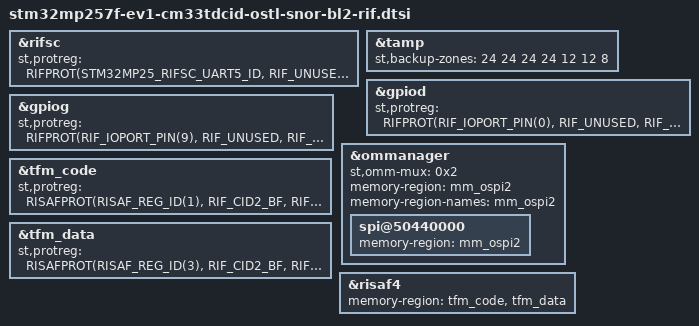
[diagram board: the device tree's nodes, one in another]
// SPDX-License-Identifier: (GPL-2.0-only OR BSD-3-Clause)
/*
 * Copyright (C) STMicroelectronics 2022 - All Rights Reserved
 */

/*
 * stm32mp257f device tree configuration
 * Project : ostl
 * Generated by XLmx tool version 2.8 - 2/28/2025 4:09:34 PM
 */

&rifsc {
	st,protreg = <
		RIFPROT(STM32MP25_RIFSC_UART5_ID, RIF_UNUSED, RIF_UNLOCK, RIF_SEC, RIF_PRIV, RIF_CID2, RIF_SEM_DIS, RIF_CFEN)
		RIFPROT(STM32MP25_RIFSC_I2C7_ID, RIF_UNUSED, RIF_UNLOCK, RIF_SEC, RIF_PRIV, RIF_CID2, RIF_SEM_DIS, RIF_CFEN)
		RIFPROT(STM32MP25_RIFSC_RNG_ID, RIF_UNUSED, RIF_UNLOCK, RIF_SEC, RIF_PRIV, RIF_CID2, RIF_SEM_DIS, RIF_CFEN)
	>;
};

&tamp {
	st,backup-zones = <24 24 24 24 12 12 8>;
};

&gpiod {
	st,protreg = <
		RIFPROT(RIF_IOPORT_PIN(0), RIF_UNUSED, RIF_UNLOCK, RIF_SEC, RIF_PRIV, RIF_CID2, RIF_SEM_DIS, RIF_CFEN)
		RIFPROT(RIF_IOPORT_PIN(3), RIF_UNUSED, RIF_UNLOCK, RIF_SEC, RIF_PRIV, RIF_CID2, RIF_SEM_DIS, RIF_CFEN)
		RIFPROT(RIF_IOPORT_PIN(4), RIF_UNUSED, RIF_UNLOCK, RIF_SEC, RIF_PRIV, RIF_CID2, RIF_SEM_DIS, RIF_CFEN)
		RIFPROT(RIF_IOPORT_PIN(5), RIF_UNUSED, RIF_UNLOCK, RIF_SEC, RIF_PRIV, RIF_CID2, RIF_SEM_DIS, RIF_CFEN)
		RIFPROT(RIF_IOPORT_PIN(6), RIF_UNUSED, RIF_UNLOCK, RIF_SEC, RIF_PRIV, RIF_CID2, RIF_SEM_DIS, RIF_CFEN)
		RIFPROT(RIF_IOPORT_PIN(7), RIF_UNUSED, RIF_UNLOCK, RIF_SEC, RIF_PRIV, RIF_CID2, RIF_SEM_DIS, RIF_CFEN)
		RIFPROT(RIF_IOPORT_PIN(14), RIF_UNUSED, RIF_UNLOCK, RIF_SEC, RIF_PRIV, RIF_CID2, RIF_SEM_DIS, RIF_CFEN)
		RIFPROT(RIF_IOPORT_PIN(15), RIF_UNUSED, RIF_UNLOCK, RIF_SEC, RIF_PRIV, RIF_CID2, RIF_SEM_DIS, RIF_CFEN)
	>;
};

&gpiog {
	st,protreg = <
		RIFPROT(RIF_IOPORT_PIN(9), RIF_UNUSED, RIF_UNLOCK, RIF_SEC, RIF_PRIV, RIF_CID2, RIF_SEM_DIS, RIF_CFEN)
		RIFPROT(RIF_IOPORT_PIN(10), RIF_UNUSED, RIF_UNLOCK, RIF_SEC, RIF_PRIV, RIF_CID2, RIF_SEM_DIS, RIF_CFEN)
	>;
};

&ommanager {
	st,omm-mux = <0x2>;
	memory-region = <&mm_ospi2>;
	memory-region-names = "mm_ospi2";

	spi@50440000 {
		memory-region = <&mm_ospi2>;
	};
};

&tfm_code {
	st,protreg = <RISAFPROT(RISAF_REG_ID(1), RIF_CID2_BF, RIF_CID2_BF, RIF_UNUSED, RIF_SEC, RIF_ENC_EN, RIF_BREN_EN)>;
};

&tfm_data {
	st,protreg = <RISAFPROT(RISAF_REG_ID(3), RIF_CID2_BF, RIF_CID2_BF, RIF_UNUSED, RIF_SEC, RIF_ENC_EN, RIF_BREN_EN)>;
};

&risaf4 {
	memory-region = <&tfm_code>, <&tfm_data>;
};
